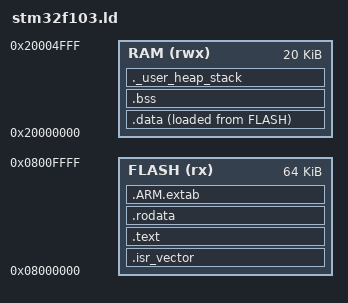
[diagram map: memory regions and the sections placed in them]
/* STM32F103C8T6 Linker Script - Sample for testing GCC Map View */

ENTRY(Reset_Handler)

MEMORY
{
    FLASH (rx)  : ORIGIN = 0x08000000, LENGTH = 64K
    RAM (rwx)   : ORIGIN = 0x20000000, LENGTH = 20K
}

SECTIONS
{
    .isr_vector : {
        . = ALIGN(4);
        KEEP(*(.isr_vector))
        . = ALIGN(4);
    } > FLASH

    .text : {
        . = ALIGN(4);
        *(.text)
        *(.text*)
        *(.glue_7)
        *(.glue_7t)

        KEEP(*(.init))
        KEEP(*(.fini))

        . = ALIGN(4);
        _etext = .;
    } > FLASH

    .rodata : {
        . = ALIGN(4);
        *(.rodata)
        *(.rodata*)
        . = ALIGN(4);
    } > FLASH

    .ARM.extab : {
        *(.ARM.extab* .gnu.linkonce.armextab.*)
    } > FLASH

    .data : {
        . = ALIGN(4);
        _sdata = .;
        *(.data)
        *(.data*)
        . = ALIGN(4);
        _edata = .;
    } > RAM AT> FLASH

    .bss : {
        . = ALIGN(4);
        _sbss = .;
        __bss_start__ = _sbss;
        *(.bss)
        *(.bss*)
        *(COMMON)
        . = ALIGN(4);
        _ebss = .;
        __bss_end__ = _ebss;
    } > RAM

    ._user_heap_stack : {
        . = ALIGN(8);
        PROVIDE(end = .);
        PROVIDE(_end = .);
        . = . + 0x200;  /* Min heap */
        . = . + 0x400;  /* Min stack */
        . = ALIGN(8);
    } > RAM
}
